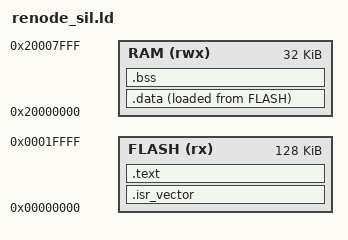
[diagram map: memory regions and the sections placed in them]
/* Linker script for the Renode SIL target.
 * Flash: 128 KiB at 0x00000000, RAM: 32 KiB at 0x20000000.
 * Matches the geometry declared in renode/lp_mspm0g3507.repl. */

ENTRY(Reset_Handler)

MEMORY
{
    FLASH (rx)  : ORIGIN = 0x00000000, LENGTH = 128K
    RAM   (rwx) : ORIGIN = 0x20000000, LENGTH = 32K
}

_stack_top = ORIGIN(RAM) + LENGTH(RAM);

SECTIONS
{
    .isr_vector :
    {
        KEEP(*(.isr_vector))
    } > FLASH

    .text :
    {
        *(.text*)
        *(.rodata*)
        . = ALIGN(4);
        _sidata = LOADADDR(.data);
    } > FLASH

    .data :
    {
        . = ALIGN(4);
        _sdata = .;
        *(.data*)
        . = ALIGN(4);
        _edata = .;
    } > RAM AT> FLASH

    .bss (NOLOAD) :
    {
        . = ALIGN(4);
        _sbss = .;
        *(.bss*)
        *(COMMON)
        . = ALIGN(4);
        _ebss = .;
    } > RAM

    _heap_start = .;
    _end = .;
    end = .;
    PROVIDE(end = .);
}
